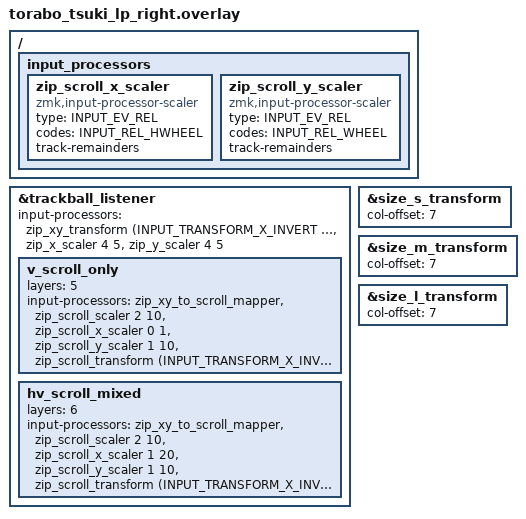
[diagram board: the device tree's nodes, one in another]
#include "torabo_tsuki_lp.dtsi"
#include <input/processors.dtsi>
#include <dt-bindings/zmk/input_transform.h>
#include <zephyr/dt-bindings/input/input-event-codes.h>

/* 右手トラックボール設定
 * - 通常（カーソル）: XY反転 + 0.6倍（3/5）
 * - layer 5（スクロール）:
 *     横 0.5倍（1/2）
 *     縦 1.0倍（変更なし）
 *     横方向だけ反転（感覚に合わせる）
 */

/ {
    input_processors {
        zip_scroll_x_scaler: zip_scroll_x_scaler {
            compatible = "zmk,input-processor-scaler";
            #input-processor-cells = <2>;
            type = <INPUT_EV_REL>;
            codes = <INPUT_REL_HWHEEL>;
            track-remainders;
        };

        zip_scroll_y_scaler: zip_scroll_y_scaler {
            compatible = "zmk,input-processor-scaler";
            #input-processor-cells = <2>;
            type = <INPUT_EV_REL>;
            codes = <INPUT_REL_WHEEL>;
            track-remainders;
        };
    };
};




&trackball_listener {
    /* 通常時（カーソル用）：XY反転 + 0.8倍 */
    input-processors = <
        &zip_xy_transform (INPUT_TRANSFORM_X_INVERT | INPUT_TRANSFORM_Y_INVERT)
        &zip_x_scaler 4 5
        &zip_y_scaler 4 5
    >;

    /* レイヤー 5：縦スクロールのみ */
    v_scroll_only {
        layers = <5>;
        input-processors = <
            &zip_xy_to_scroll_mapper
            &zip_scroll_scaler 2 10
            &zip_scroll_x_scaler 0 1  /* 横方向を 0 倍にして動かなくします */
            &zip_scroll_y_scaler 1 10 /* 縦方向は通常の感度 */
            &zip_scroll_transform (INPUT_TRANSFORM_X_INVERT) /* お好みの方向に反転 */
        >;
    };

    /* レイヤー 6：縦横スクロール（横は鈍感設定） */
    hv_scroll_mixed {
        layers = <6>;
        input-processors = <
            &zip_xy_to_scroll_mapper
            &zip_scroll_scaler 2 10
            &zip_scroll_x_scaler 1 20 /* 横方向を 1/20 倍で鈍感にします */
            &zip_scroll_y_scaler 1 10 /* 縦方向は通常の感度 */
            &zip_scroll_transform (INPUT_TRANSFORM_X_INVERT) /* お好みの方向に反転 */
        >;
    };
};

/* キーレイアウト用の transform は元のまま */
&size_s_transform {
    col-offset = <7>;
};

&size_m_transform {
    col-offset = <7>;
};

&size_l_transform {
    col-offset = <7>;
};
